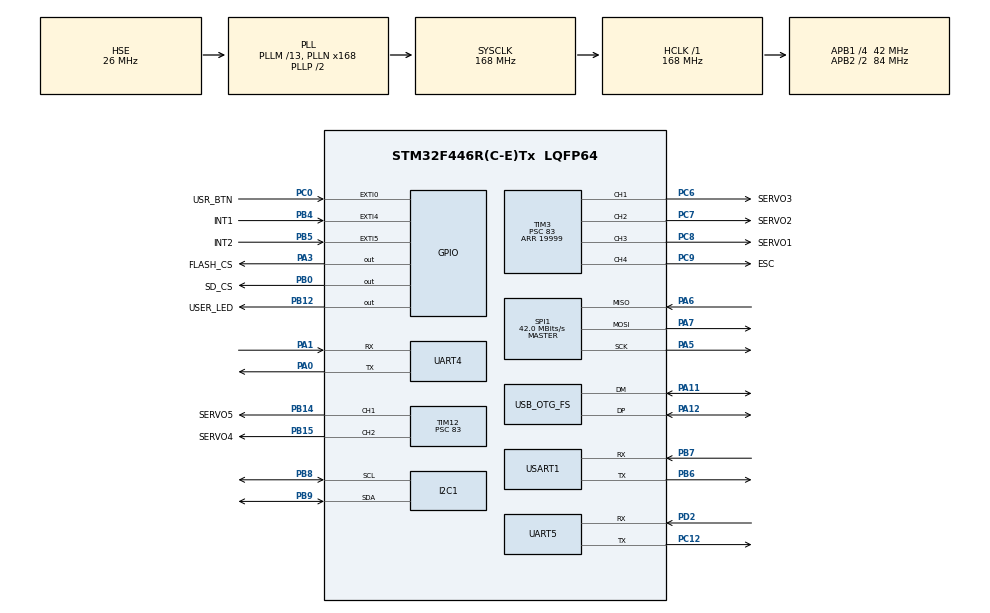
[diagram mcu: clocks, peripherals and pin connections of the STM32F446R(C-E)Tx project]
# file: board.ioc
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Dma.I2C1_RX.4.Direction=DMA_PERIPH_TO_MEMORY
Dma.I2C1_RX.4.FIFOMode=DMA_FIFOMODE_DISABLE
Dma.I2C1_RX.4.Instance=DMA1_Stream5
Dma.I2C1_RX.4.MemDataAlignment=DMA_MDATAALIGN_BYTE
Dma.I2C1_RX.4.MemInc=DMA_MINC_ENABLE
Dma.I2C1_RX.4.Mode=DMA_NORMAL
Dma.I2C1_RX.4.PeriphDataAlignment=DMA_PDATAALIGN_BYTE
Dma.I2C1_RX.4.PeriphInc=DMA_PINC_DISABLE
Dma.I2C1_RX.4.Priority=DMA_PRIORITY_LOW
Dma.I2C1_TX.5.Direction=DMA_MEMORY_TO_PERIPH
Dma.I2C1_TX.5.FIFOMode=DMA_FIFOMODE_DISABLE
Dma.I2C1_TX.5.Instance=DMA1_Stream6
Dma.I2C1_TX.5.MemDataAlignment=DMA_MDATAALIGN_BYTE
Dma.I2C1_TX.5.MemInc=DMA_MINC_ENABLE
Dma.I2C1_TX.5.Mode=DMA_NORMAL
Dma.I2C1_TX.5.PeriphDataAlignment=DMA_PDATAALIGN_BYTE
Dma.I2C1_TX.5.PeriphInc=DMA_PINC_DISABLE
Dma.I2C1_TX.5.Priority=DMA_PRIORITY_LOW
Dma.Request0=SPI1_TX
Dma.Request1=SPI1_RX
Dma.Request2=USART1_RX
Dma.Request3=USART1_TX
Dma.Request4=I2C1_RX
Dma.Request5=I2C1_TX
Dma.Request6=UART4_RX
Dma.Request7=UART4_TX
Dma.Request8=UART5_RX
Dma.Request9=UART5_TX
Dma.SPI1_RX.1.Direction=DMA_PERIPH_TO_MEMORY
Dma.SPI1_RX.1.FIFOMode=DMA_FIFOMODE_DISABLE
Dma.SPI1_RX.1.Instance=DMA2_Stream0
Dma.SPI1_RX.1.MemDataAlignment=DMA_MDATAALIGN_BYTE
Dma.SPI1_RX.1.MemInc=DMA_MINC_ENABLE
Dma.SPI1_RX.1.Mode=DMA_NORMAL
Dma.SPI1_RX.1.PeriphDataAlignment=DMA_PDATAALIGN_BYTE
Dma.SPI1_RX.1.PeriphInc=DMA_PINC_DISABLE
Dma.SPI1_RX.1.Priority=DMA_PRIORITY_LOW
Dma.SPI1_TX.0.Direction=DMA_MEMORY_TO_PERIPH
Dma.SPI1_TX.0.FIFOMode=DMA_FIFOMODE_DISABLE
Dma.SPI1_TX.0.Instance=DMA2_Stream3
Dma.SPI1_TX.0.MemDataAlignment=DMA_MDATAALIGN_BYTE
Dma.SPI1_TX.0.MemInc=DMA_MINC_ENABLE
Dma.SPI1_TX.0.Mode=DMA_NORMAL
Dma.SPI1_TX.0.PeriphDataAlignment=DMA_PDATAALIGN_BYTE
Dma.SPI1_TX.0.PeriphInc=DMA_PINC_DISABLE
Dma.SPI1_TX.0.Priority=DMA_PRIORITY_LOW
Dma.UART4_RX.6.Direction=DMA_PERIPH_TO_MEMORY
Dma.UART4_RX.6.FIFOMode=DMA_FIFOMODE_DISABLE
Dma.UART4_RX.6.Instance=DMA1_Stream2
Dma.UART4_RX.6.MemDataAlignment=DMA_MDATAALIGN_BYTE
Dma.UART4_RX.6.MemInc=DMA_MINC_ENABLE
Dma.UART4_RX.6.Mode=DMA_CIRCULAR
Dma.UART4_RX.6.PeriphDataAlignment=DMA_PDATAALIGN_BYTE
Dma.UART4_RX.6.PeriphInc=DMA_PINC_DISABLE
Dma.UART4_RX.6.Priority=DMA_PRIORITY_LOW
Dma.UART4_TX.7.Direction=DMA_MEMORY_TO_PERIPH
Dma.UART4_TX.7.FIFOMode=DMA_FIFOMODE_DISABLE
Dma.UART4_TX.7.Instance=DMA1_Stream4
Dma.UART4_TX.7.MemDataAlignment=DMA_MDATAALIGN_BYTE
Dma.UART4_TX.7.MemInc=DMA_MINC_ENABLE
Dma.UART4_TX.7.Mode=DMA_NORMAL
Dma.UART4_TX.7.PeriphDataAlignment=DMA_PDATAALIGN_BYTE
Dma.UART4_TX.7.PeriphInc=DMA_PINC_DISABLE
Dma.UART4_TX.7.Priority=DMA_PRIORITY_LOW
Dma.UART5_RX.8.Direction=DMA_PERIPH_TO_MEMORY
Dma.UART5_RX.8.FIFOMode=DMA_FIFOMODE_DISABLE
Dma.UART5_RX.8.Instance=DMA1_Stream0
Dma.UART5_RX.8.MemDataAlignment=DMA_MDATAALIGN_BYTE
Dma.UART5_RX.8.MemInc=DMA_MINC_ENABLE
Dma.UART5_RX.8.Mode=DMA_NORMAL
Dma.UART5_RX.8.PeriphDataAlignment=DMA_PDATAALIGN_BYTE
Dma.UART5_RX.8.PeriphInc=DMA_PINC_DISABLE
Dma.UART5_RX.8.Priority=DMA_PRIORITY_LOW
Dma.UART5_TX.9.Direction=DMA_MEMORY_TO_PERIPH
Dma.UART5_TX.9.FIFOMode=DMA_FIFOMODE_DISABLE
Dma.UART5_TX.9.Instance=DMA1_Stream7
Dma.UART5_TX.9.MemDataAlignment=DMA_MDATAALIGN_BYTE
Dma.UART5_TX.9.MemInc=DMA_MINC_ENABLE
Dma.UART5_TX.9.Mode=DMA_NORMAL
Dma.UART5_TX.9.PeriphDataAlignment=DMA_PDATAALIGN_BYTE
Dma.UART5_TX.9.PeriphInc=DMA_PINC_DISABLE
Dma.UART5_TX.9.Priority=DMA_PRIORITY_LOW
Dma.USART1_RX.2.Direction=DMA_PERIPH_TO_MEMORY
Dma.USART1_RX.2.FIFOMode=DMA_FIFOMODE_DISABLE
Dma.USART1_RX.2.Instance=DMA2_Stream2
Dma.USART1_RX.2.MemDataAlignment=DMA_MDATAALIGN_BYTE
Dma.USART1_RX.2.MemInc=DMA_MINC_ENABLE
Dma.USART1_RX.2.Mode=DMA_CIRCULAR
Dma.USART1_RX.2.PeriphDataAlignment=DMA_PDATAALIGN_BYTE
Dma.USART1_RX.2.PeriphInc=DMA_PINC_DISABLE
Dma.USART1_RX.2.Priority=DMA_PRIORITY_LOW
Dma.USART1_TX.3.Direction=DMA_MEMORY_TO_PERIPH
Dma.USART1_TX.3.FIFOMode=DMA_FIFOMODE_DISABLE
Dma.USART1_TX.3.Instance=DMA2_Stream7
Dma.USART1_TX.3.MemDataAlignment=DMA_MDATAALIGN_BYTE
Dma.USART1_TX.3.MemInc=DMA_MINC_ENABLE
Dma.USART1_TX.3.Mode=DMA_NORMAL
Dma.USART1_TX.3.PeriphDataAlignment=DMA_PDATAALIGN_BYTE
Dma.USART1_TX.3.PeriphInc=DMA_PINC_DISABLE
Dma.USART1_TX.3.Priority=DMA_PRIORITY_LOW
FREERTOS.INCLUDE_uxTaskGetStackHighWaterMark2=1
FREERTOS.Tasks01=defaultTask,24,128,StartDefaultTask,Default,NULL,Dynamic,NULL,NULL
FREERTOS.configCHECK_FOR_STACK_OVERFLOW=2
FREERTOS.configTOTAL_HEAP_SIZE=32768
FREERTOS.configUSE_MALLOC_FAILED_HOOK=1
Mcu.Family=STM32F4
Mcu.Name=STM32F446R(C-E)Tx
Mcu.Package=LQFP64
NVIC.DMA1_Stream0_IRQn=true\:5\:0\:false\:false\:true\:true\:false\:true\:true
NVIC.DMA1_Stream2_IRQn=true\:5\:0\:false\:false\:true\:true\:false\:true\:true
NVIC.DMA1_Stream4_IRQn=true\:5\:0\:false\:false\:true\:true\:false\:true\:true
NVIC.DMA1_Stream5_IRQn=true\:5\:0\:false\:false\:true\:false\:false\:true\:true
NVIC.DMA1_Stream6_IRQn=true\:5\:0\:false\:false\:true\:true\:false\:true\:true
NVIC.DMA1_Stream7_IRQn=true\:5\:0\:false\:false\:true\:true\:false\:true\:true
NVIC.DMA2_Stream0_IRQn=true\:5\:0\:false\:false\:true\:true\:false\:true\:true
NVIC.DMA2_Stream2_IRQn=true\:5\:0\:false\:false\:true\:true\:false\:true\:true
NVIC.DMA2_Stream3_IRQn=true\:5\:0\:false\:false\:true\:true\:false\:true\:true
NVIC.DMA2_Stream7_IRQn=true\:5\:0\:false\:false\:true\:true\:false\:true\:true
NVIC.EXTI0_IRQn=true\:5\:0\:false\:false\:true\:true\:true\:true\:true
NVIC.EXTI4_IRQn=true\:5\:0\:false\:false\:true\:true\:true\:true\:true
NVIC.EXTI9_5_IRQn=true\:5\:0\:false\:false\:true\:true\:true\:true\:true
NVIC.I2C1_ER_IRQn=true\:5\:0\:false\:false\:true\:true\:true\:true\:true
NVIC.OTG_FS_IRQn=true\:5\:0\:false\:false\:true\:true\:false\:true\:true
NVIC.PriorityGroup=NVIC_PRIORITYGROUP_4
NVIC.TIM1_UP_TIM10_IRQn=true\:15\:0\:false\:false\:true\:false\:false\:true\:true
NVIC.TimeBase=TIM1_UP_TIM10_IRQn
NVIC.TimeBaseIP=TIM1
PA0-WKUP.Mode=Asynchronous
PA0-WKUP.Signal=UART4_TX
PA1.Mode=Asynchronous
PA1.Signal=UART4_RX
PA11.Mode=Device_Only
PA11.Signal=USB_OTG_FS_DM
PA12.Mode=Device_Only
PA12.Signal=USB_OTG_FS_DP
PA13.Mode=Serial_Wire
PA13.Signal=SYS_JTMS-SWDIO
PA14.Mode=Serial_Wire
PA14.Signal=SYS_JTCK-SWCLK
PA3.GPIO_Label=FLASH_CS
PA3.PinState=GPIO_PIN_SET
PA3.Signal=GPIO_Output
PA5.Mode=Full_Duplex_Master
PA5.Signal=SPI1_SCK
PA6.Mode=Full_Duplex_Master
PA6.Signal=SPI1_MISO
PA7.Mode=Full_Duplex_Master
PA7.Signal=SPI1_MOSI
PB0.GPIO_Label=SD_CS
PB0.PinState=GPIO_PIN_SET
PB0.Signal=GPIO_Output
PB12.GPIO_Label=USER_LED
PB12.PinState=GPIO_PIN_SET
PB12.Signal=GPIO_Output
PB14.GPIO_Label=SERVO5
PB14.Signal=S_TIM12_CH1
PB15.GPIO_Label=SERVO4
PB15.Signal=S_TIM12_CH2
PB4.GPIO_Label=INT1
PB4.Signal=GPXTI4
PB5.GPIO_Label=INT2
PB5.Signal=GPXTI5
PB6.Mode=Asynchronous
PB6.Signal=USART1_TX
PB7.Mode=Asynchronous
PB7.Signal=USART1_RX
PB8.Mode=I2C
PB8.Signal=I2C1_SCL
PB9.Mode=I2C
PB9.Signal=I2C1_SDA
PC0.GPIO_Label=USR_BTN
PC0.GPIO_ModeDefaultEXTI=GPIO_MODE_IT_RISING_FALLING
PC0.GPIO_PuPd=GPIO_NOPULL
PC0.Signal=GPXTI0
PC12.Mode=Asynchronous
PC12.Signal=UART5_TX
PC6.GPIO_Label=SERVO3
PC6.Signal=S_TIM3_CH1
PC7.GPIO_Label=SERVO2
PC7.Signal=S_TIM3_CH2
PC8.GPIO_Label=SERVO1
PC8.Signal=S_TIM3_CH3
PC9.GPIO_Label=ESC
PC9.Signal=S_TIM3_CH4
PD2.Mode=Asynchronous
PD2.Signal=UART5_RX
PH0-OSC_IN.Mode=HSE-External-Oscillator
PH0-OSC_IN.Signal=RCC_OSC_IN
PH1-OSC_OUT.Mode=HSE-External-Oscillator
PH1-OSC_OUT.Signal=RCC_OSC_OUT
ProjectManager.HeapSize=0x200
ProjectManager.StackSize=0x400
ProjectManager.TargetToolchain=CMake
RCC.AHBFreq_Value=168000000
RCC.APB1CLKDivider=RCC_HCLK_DIV4
RCC.APB1Freq_Value=42000000
RCC.APB1TimFreq_Value=84000000
RCC.APB2CLKDivider=RCC_HCLK_DIV2
RCC.APB2Freq_Value=84000000
RCC.APB2TimFreq_Value=168000000
RCC.CortexFreq_Value=168000000
RCC.HCLKFreq_Value=168000000
RCC.HSE_VALUE=26000000
RCC.PLLM=13
RCC.PLLN=168
RCC.PLLQ=7
RCC.PLLSAIM=13
RCC.PLLSAIN=96
RCC.PLLSAIP=RCC_PLLSAIP_DIV4
RCC.SYSCLKFreq_VALUE=168000000
RCC.SYSCLKSource=RCC_SYSCLKSOURCE_PLLCLK
RCC.USBFreq_Value=48000000
RCC.VCOOutputFreq_Value=336000000
SH.S_TIM12_CH1.0=TIM12_CH1,PWM Generation1 CH1
SH.S_TIM12_CH2.0=TIM12_CH2,PWM Generation2 CH2
SH.S_TIM3_CH1.0=TIM3_CH1,PWM Generation1 CH1
SH.S_TIM3_CH2.0=TIM3_CH2,PWM Generation2 CH2
SH.S_TIM3_CH3.0=TIM3_CH3,PWM Generation3 CH3
SH.S_TIM3_CH4.0=TIM3_CH4,PWM Generation4 CH4
SPI1.BaudRatePrescaler=SPI_BAUDRATEPRESCALER_2
SPI1.CalculateBaudRate=42.0 MBits/s
SPI1.Direction=SPI_DIRECTION_2LINES
SPI1.Mode=SPI_MODE_MASTER
SPI1.VirtualType=VM_MASTER
TIM12.Channel-PWM\ Generation1\ CH1=TIM_CHANNEL_1
TIM12.Channel-PWM\ Generation2\ CH2=TIM_CHANNEL_2
TIM12.Period=19999
TIM12.Prescaler=83
TIM3.Channel-PWM\ Generation1\ CH1=TIM_CHANNEL_1
TIM3.Channel-PWM\ Generation2\ CH2=TIM_CHANNEL_2
TIM3.Channel-PWM\ Generation3\ CH3=TIM_CHANNEL_3
TIM3.Channel-PWM\ Generation4\ CH4=TIM_CHANNEL_4
TIM3.Period=19999
TIM3.Prescaler=83
UART4.VirtualMode=Asynchronous
UART5.VirtualMode=Asynchronous
USART1.VirtualMode=VM_ASYNC
USB_DEVICE.CLASS_NAME_FS=CDC
USB_DEVICE.VirtualMode-CDC_FS=Cdc
USB_DEVICE.VirtualModeFS=Cdc_FS
USB_OTG_FS.VirtualMode=Device_Only
VP_FREERTOS_VS_CMSIS_V2.Mode=CMSIS_V2
VP_SYS_VS_tim1.Mode=TIM1
VP_USB_DEVICE_VS_USB_DEVICE_CDC_FS.Mode=CDC_FS
board=custom

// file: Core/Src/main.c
/* USER CODE BEGIN Header */
/**
 ******************************************************************************
 * @file           : main.c
 * @brief          : Main program body
 ******************************************************************************
 * @attention
 *
 * Copyright (c) 2026 STMicroelectronics.
 * All rights reserved.
 *
 * This software is licensed under terms that can be found in the
 *LICENSE file in the root directory of this software component. If no
 *LICENSE file comes with this software, it is provided AS-IS.
 *
 ******************************************************************************
 */
/* USER CODE END Header */
#include "main.h"
#include "cmsis_os.h"
#include "dma.h"
#include "i2c.h"
#include "spi.h"
#include "tim.h"
#include "usart.h"
#include "usb_device.h"
#include "gpio.h"

/* USER CODE BEGIN Includes */
#include "app/app.hpp"
/* USER CODE END Includes */

void SystemClock_Config(void);
void MX_FREERTOS_Init(void);

int main(void)
{

  /* MCU Configuration--------------------------------------------------------*/

  /* Reset of all peripherals, Initializes the Flash interface and the Systick. */
  HAL_Init();

  /* Configure the system clock */
  SystemClock_Config();

  /* Initialize all configured peripherals */
  MX_GPIO_Init();
  MX_DMA_Init();
  MX_I2C1_Init();
  MX_SPI1_Init();
  MX_TIM3_Init();
  MX_UART4_Init();
  MX_TIM12_Init();
  MX_UART5_Init();
  MX_USART1_UART_Init();
  /* USER CODE BEGIN 2 */
  {
    static const uint8_t k_boot[] =
        "\r\n[boot] gambos — UART5 @ 115200 (main, before "
        "scheduler)\r\n";
    (void)HAL_UART_Transmit(
        &huart5, k_boot, sizeof(k_boot) - 1U, HAL_MAX_DELAY);
  }
  app_init();
  /* USER CODE END 2 */

  /* Init scheduler */
  osKernelInitialize();  /* Call init function for freertos objects (in cmsis_os2.c) */
  MX_FREERTOS_Init();

  /* Start scheduler */
  osKernelStart();

  /* We should never get here as control is now taken by the scheduler */

  /* Infinite loop */
    while (1) {

    }
}

void SystemClock_Config(void)
{
  RCC_OscInitTypeDef RCC_OscInitStruct = {0};
  RCC_ClkInitTypeDef RCC_ClkInitStruct = {0};

  /** Configure the main internal regulator output voltage
  */
  __HAL_RCC_PWR_CLK_ENABLE();
  __HAL_PWR_VOLTAGESCALING_CONFIG(PWR_REGULATOR_VOLTAGE_SCALE1);

  /** Initializes the RCC Oscillators according to the specified parameters
  * in the RCC_OscInitTypeDef structure.
  */
  RCC_OscInitStruct.OscillatorType = RCC_OSCILLATORTYPE_HSE;
  RCC_OscInitStruct.HSEState = RCC_HSE_ON;
  RCC_OscInitStruct.PLL.PLLState = RCC_PLL_ON;
  RCC_OscInitStruct.PLL.PLLSource = RCC_PLLSOURCE_HSE;
  RCC_OscInitStruct.PLL.PLLM = 13;
  RCC_OscInitStruct.PLL.PLLN = 168;
  RCC_OscInitStruct.PLL.PLLP = RCC_PLLP_DIV2;
  RCC_OscInitStruct.PLL.PLLQ = 7;
  RCC_OscInitStruct.PLL.PLLR = 2;
  if (HAL_RCC_OscConfig(&RCC_OscInitStruct) != HAL_OK)
  {
    Error_Handler();
  }

  /** Initializes the CPU, AHB and APB buses clocks
  */
  RCC_ClkInitStruct.ClockType = RCC_CLOCKTYPE_HCLK|RCC_CLOCKTYPE_SYSCLK
                              |RCC_CLOCKTYPE_PCLK1|RCC_CLOCKTYPE_PCLK2;
  RCC_ClkInitStruct.SYSCLKSource = RCC_SYSCLKSOURCE_PLLCLK;
  RCC_ClkInitStruct.AHBCLKDivider = RCC_SYSCLK_DIV1;
  RCC_ClkInitStruct.APB1CLKDivider = RCC_HCLK_DIV4;
  RCC_ClkInitStruct.APB2CLKDivider = RCC_HCLK_DIV2;

  if (HAL_RCC_ClockConfig(&RCC_ClkInitStruct, FLASH_LATENCY_5) != HAL_OK)
  {
    Error_Handler();
  }
}

void HAL_TIM_PeriodElapsedCallback(TIM_HandleTypeDef *htim)
{
  if (htim->Instance == TIM1)
  {
    HAL_IncTick();
  }
}

void Error_Handler(void)
{
  /* USER CODE BEGIN Error_Handler_Debug */
    /* User can add his own implementation to report the HAL error
     * return state */
    __disable_irq();
    while (1) {}
  /* USER CODE END Error_Handler_Debug */
}
#ifdef USE_FULL_ASSERT
/**
  * @brief  Reports the name of the source file and the source line number
  *         where the assert_param error has occurred.
  * @param  file: pointer to the source file name
  * @param  line: assert_param error line source number
  * @retval None
  */
void assert_failed(uint8_t *file, uint32_t line)
{
  /* USER CODE BEGIN 6 */
    /* User can add his own implementation to report the file name and
       line number, ex: printf("Wrong parameters value: file %s on
       line %d\r\n", file, line) */
  /* USER CODE END 6 */
}
#endif /* USE_FULL_ASSERT */

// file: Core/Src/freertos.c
/* USER CODE BEGIN Header */
/**
 ******************************************************************************
 * File Name          : freertos.c
 * Description        : Code for freertos applications
 ******************************************************************************
 * @attention
 *
 * Copyright (c) 2026 STMicroelectronics.
 * All rights reserved.
 *
 * This software is licensed under terms that can be found in the
 *LICENSE file in the root directory of this software component. If no
 *LICENSE file comes with this software, it is provided AS-IS.
 *
 ******************************************************************************
 */
/* USER CODE END Header */

#include "FreeRTOS.h"
#include "task.h"
#include "main.h"
#include "cmsis_os.h"

/* Definitions for defaultTask */
osThreadId_t defaultTaskHandle;
const osThreadAttr_t defaultTask_attributes = {
  .name = "defaultTask",
  .stack_size = 128 * 4,
  .priority = (osPriority_t) osPriorityNormal,
};

void StartDefaultTask(void *argument);

extern void MX_USB_DEVICE_Init(void);
void MX_FREERTOS_Init(void); /* (MISRA C 2004 rule 8.1) */

/* Hook prototypes */
void vApplicationStackOverflowHook(xTaskHandle xTask, signed char *pcTaskName);
void vApplicationMallocFailedHook(void);

/* USER CODE BEGIN 4 */
void vApplicationStackOverflowHook(xTaskHandle xTask, signed char *pcTaskName)
{
   /* Run time stack overflow checking is performed if
   configCHECK_FOR_STACK_OVERFLOW is defined to 1 or 2. This hook function is
   called if a stack overflow is detected. */
}
/* USER CODE END 4 */

/* USER CODE BEGIN 5 */
void vApplicationMallocFailedHook(void)
{
   /* vApplicationMallocFailedHook() will only be called if
   configUSE_MALLOC_FAILED_HOOK is set to 1 in FreeRTOSConfig.h. It is a hook
   function that will get called if a call to pvPortMalloc() fails.
   pvPortMalloc() is called internally by the kernel whenever a task, queue,
   timer or semaphore is created. It is also called by various parts of the
   demo application. If heap_1.c or heap_2.c are used, then the size of the
   heap available to pvPortMalloc() is defined by configTOTAL_HEAP_SIZE in
   FreeRTOSConfig.h, and the xPortGetFreeHeapSize() API function can be used
   to query the size of free heap space that remains (although it does not
   provide information on how the remaining heap might be fragmented). */
}
/* USER CODE END 5 */

void MX_FREERTOS_Init(void) {

  /* Create the thread(s) */
  /* creation of defaultTask */
  defaultTaskHandle = osThreadNew(StartDefaultTask, NULL, &defaultTask_attributes);

}

void StartDefaultTask(void *argument)
{
  /* init code for USB_DEVICE */
  MX_USB_DEVICE_Init();
    for (;;) {
        osDelay(1);
    }
}
